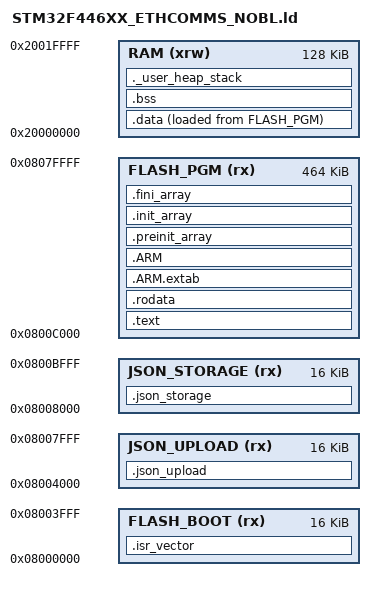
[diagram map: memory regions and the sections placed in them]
/*
******************************************************************************
**
** @file        : LinkerScript.ld
**
** @author      : Auto-generated by STM32CubeIDE
**
** @brief       : Linker script for STM32F446xxx Devices from STM32F4 series
**                      512Kbytes FLASH
**                      128Kbytes RAM
**
**                Set heap size, stack size and stack location according
**                to application requirements.
**
**                Set memory bank area and size if external memory is used
**
**  Target      : STMicroelectronics STM32
**
**  Distribution: The file is distributed as is, without any warranty
**                of any kind.
**
******************************************************************************
** @attention
**
** <h2><center>&copy; Copyright (c) 2021 STMicroelectronics.
** All rights reserved.</center></h2>
**
** This software component is licensed by ST under BSD 3-Clause license,
** the "License"; You may not use this file except in compliance with the
** License. You may obtain a copy of the License at:
**                        opensource.org/licenses/BSD-3-Clause
**
******************************************************************************
*/

/* Entry Point */
ENTRY(Reset_Handler)

/* Highest address of the user mode stack */
_estack = ORIGIN(RAM) + LENGTH(RAM); /* end of "RAM" Ram type memory */

_Min_Heap_Size = 0x2000; /* required amount of heap */
_Min_Stack_Size = 0x400; /* required amount of stack */

/* Flash sizes */
_FLASH_TOTAL_SIZE = 512K;
_FLASH_BOOT_SIZE = 16K;  
_FLASH_JSON_UPLOAD_SIZE = 16K;
_FLASH_JSON_STORAGE_SIZE = 16K;
_PGM_FLASH_AVAILABLE_SIZE = _FLASH_TOTAL_SIZE - _FLASH_BOOT_SIZE - _FLASH_JSON_UPLOAD_SIZE - _FLASH_JSON_STORAGE_SIZE;

/* Memories definition */
MEMORY
{
  RAM    (xrw)        : ORIGIN = 0x20000000,    LENGTH = 128K
  FLASH_BOOT (rx)     : ORIGIN = 0x08000000,    LENGTH = _FLASH_BOOT_SIZE         /* Sector 0 for reset and ISR vectors, debugger */
  JSON_UPLOAD  (rx)   : ORIGIN = 0x08004000,    LENGTH = _FLASH_JSON_UPLOAD_SIZE      /* Sector 1 for JSON_UPLOAD */
  JSON_STORAGE (rx)   : ORIGIN = 0x08008000,    LENGTH = _FLASH_JSON_STORAGE_SIZE     /* Sector 2 for JSON_STORAGE */  
  FLASH_PGM    (rx)   : ORIGIN = 0x0800C000,    LENGTH = _PGM_FLASH_AVAILABLE_SIZE
}

/* JSON config locations for this build target */
_ls_json_upload_start = ORIGIN(JSON_UPLOAD);
_ls_json_upload_end   = ORIGIN(JSON_UPLOAD) + LENGTH(JSON_UPLOAD);

_ls_json_storage_start = ORIGIN(JSON_STORAGE);
_ls_json_storage_end   = ORIGIN(JSON_STORAGE) + LENGTH(JSON_STORAGE);

_ls_json_upload_sector  = 1;  /* 1U = FLASH_SECTOR_1 */
_ls_json_storage_sector = 2;  /* 2U = FLASH_SECTOR_2 */

/* Sections */
SECTIONS
{
  /* The startup code into "FLASH" Rom type memory */
  .isr_vector :
  {
    . = ALIGN(4);
    KEEP(*(.isr_vector)) /* Startup code */
    . = ALIGN(4);
  } >FLASH_BOOT

  /* 2x JSON storage areas, one for uploading new flash, the other for persistent storage */  
  .json_upload (NOLOAD) :
  {
      . = ALIGN(4);
      KEEP(*(.json_upload))
      KEEP(*(.json_upload.*))
      . = ALIGN(4);
  } >JSON_UPLOAD

  .json_storage (NOLOAD) :
  {
      . = ALIGN(4);
      KEEP(*(.json_storage))
      KEEP(*(.json_storage.*))
      . = ALIGN(4);
  } >JSON_STORAGE

  /* The program code and other data into "FLASH" Rom type memory */
  .text :
  {
    . = ALIGN(4);
    *(.text)           /* .text sections (code) */
    *(.text*)          /* .text* sections (code) */
    *(.glue_7)         /* glue arm to thumb code */
    *(.glue_7t)        /* glue thumb to arm code */
    *(.eh_frame)

    KEEP (*(.init))
    KEEP (*(.fini))

    . = ALIGN(4);
    _etext = .;        /* define a global symbols at end of code */
  } >FLASH_PGM

  /* Constant data into "FLASH" Rom type memory */
  .rodata :
  {
    . = ALIGN(4);
    *(.rodata)         /* .rodata sections (constants, strings, etc.) */
    *(.rodata*)        /* .rodata* sections (constants, strings, etc.) */
    . = ALIGN(4);
  } >FLASH_PGM

  .ARM.extab   : {
    . = ALIGN(4);
    *(.ARM.extab* .gnu.linkonce.armextab.*)
    . = ALIGN(4);
  } >FLASH_PGM

  .ARM : {
    . = ALIGN(4);
    __exidx_start = .;
    *(.ARM.exidx*)
    __exidx_end = .;
    . = ALIGN(4);
  } >FLASH_PGM

  .preinit_array     :
  {
    . = ALIGN(4);
    PROVIDE_HIDDEN (__preinit_array_start = .);
    KEEP (*(.preinit_array*))
    PROVIDE_HIDDEN (__preinit_array_end = .);
    . = ALIGN(4);
  } >FLASH_PGM

  .init_array :
  {
    . = ALIGN(4);
    PROVIDE_HIDDEN (__init_array_start = .);
    KEEP (*(SORT(.init_array.*)))
    KEEP (*(.init_array*))
    PROVIDE_HIDDEN (__init_array_end = .);
    . = ALIGN(4);
  } >FLASH_PGM

  .fini_array :
  {
    . = ALIGN(4);
    PROVIDE_HIDDEN (__fini_array_start = .);
    KEEP (*(SORT(.fini_array.*)))
    KEEP (*(.fini_array*))
    PROVIDE_HIDDEN (__fini_array_end = .);
    . = ALIGN(4);
  } >FLASH_PGM

  /* Used by the startup to initialize data */
  _sidata = LOADADDR(.data);

  /* Initialized data sections into "RAM" Ram type memory */
  .data :
  {
    . = ALIGN(4);
    _sdata = .;        /* create a global symbol at data start */
    *(.data)           /* .data sections */
    *(.data*)          /* .data* sections */
    *(.RamFunc)        /* .RamFunc sections */
    *(.RamFunc*)       /* .RamFunc* sections */

    . = ALIGN(4);
    _edata = .;        /* define a global symbol at data end */

  } >RAM AT> FLASH_PGM

  /* Uninitialized data section into "RAM" Ram type memory */
  . = ALIGN(4);
  .bss :
  {
    /* This is used by the startup in order to initialize the .bss section */
    _sbss = .;         /* define a global symbol at bss start */
    __bss_start__ = _sbss;
    *(.bss)
    *(.bss*)
    *(COMMON)

    . = ALIGN(4);
    _ebss = .;         /* define a global symbol at bss end */
    __bss_end__ = _ebss;
  } >RAM

  /* User_heap_stack section, used to check that there is enough "RAM" Ram  type memory left */
  ._user_heap_stack :
  {
    . = ALIGN(8);
    PROVIDE ( end = . );
    PROVIDE ( _end = . );
    . = . + _Min_Heap_Size;
    . = . + _Min_Stack_Size;
    . = ALIGN(8);
  } >RAM

  /* Remove information from the compiler libraries */
  /DISCARD/ :
  {
    libc.a ( * )
    libm.a ( * )
    libgcc.a ( * )
  }

  .ARM.attributes 0 : { *(.ARM.attributes) }
}
